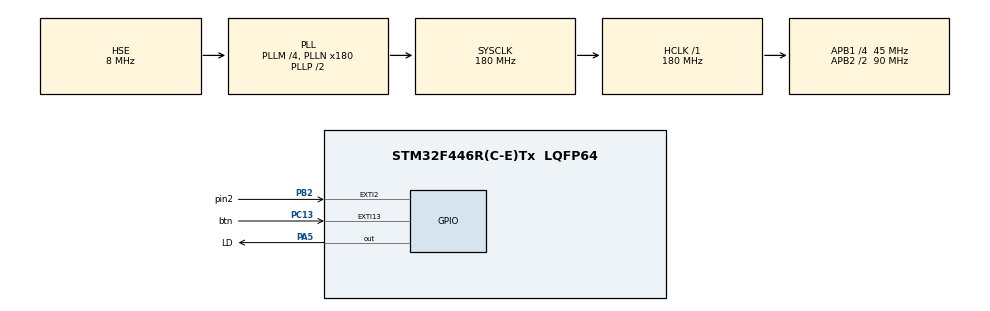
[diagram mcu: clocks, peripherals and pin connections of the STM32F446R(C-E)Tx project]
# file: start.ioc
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FREERTOS.Tasks01=defaultTask,0,128,StartDefaultTask,Default,NULL,Dynamic,NULL,NULL;led_task,0,128,start_led_task,Default,NULL,Dynamic,NULL,NULL;button_task,0,128,start_button_task,Default,NULL,Dynamic,NULL,NULL
FREERTOS.configENABLE_FPU=1
FREERTOS.configUSE_NEWLIB_REENTRANT=1
Mcu.Family=STM32F4
Mcu.Name=STM32F446R(C-E)Tx
Mcu.Package=LQFP64
NVIC.EXTI15_10_IRQn=true\:5\:0\:false\:false\:true\:true\:true\:true\:true
NVIC.EXTI2_IRQn=true\:5\:0\:false\:false\:true\:true\:true\:true\:true
NVIC.PriorityGroup=NVIC_PRIORITYGROUP_4
NVIC.TIM1_UP_TIM10_IRQn=true\:15\:0\:false\:false\:true\:false\:false\:true\:true
NVIC.TimeBase=TIM1_UP_TIM10_IRQn
NVIC.TimeBaseIP=TIM10
PA13.Mode=Serial_Wire
PA13.Signal=SYS_JTMS-SWDIO
PA14.Mode=Serial_Wire
PA14.Signal=SYS_JTCK-SWCLK
PA5.GPIO_Label=LD
PA5.Signal=GPIO_Output
PB2.GPIO_Label=pin2
PB2.GPIO_PuPd=GPIO_PULLUP
PB2.Signal=GPXTI2
PC13.GPIO_Label=btn
PC13.Signal=GPXTI13
PH0-OSC_IN.Mode=HSE-External-Oscillator
PH0-OSC_IN.Signal=RCC_OSC_IN
PH1-OSC_OUT.Mode=HSE-External-Oscillator
PH1-OSC_OUT.Signal=RCC_OSC_OUT
ProjectManager.HeapSize=0x200
ProjectManager.StackSize=0x400
ProjectManager.TargetToolchain=STM32CubeIDE
RCC.AHBFreq_Value=180000000
RCC.APB1CLKDivider=RCC_HCLK_DIV4
RCC.APB1Freq_Value=45000000
RCC.APB1TimFreq_Value=90000000
RCC.APB2CLKDivider=RCC_HCLK_DIV2
RCC.APB2Freq_Value=90000000
RCC.APB2TimFreq_Value=180000000
RCC.CortexFreq_Value=180000000
RCC.FLatency-AdvancedSettings=FLASH_LATENCY_5
RCC.HCLKFreq_Value=180000000
RCC.HSE_VALUE=8000000
RCC.HSI_VALUE=16000000
RCC.PLLM=4
RCC.PLLN=180
RCC.PLLSourceVirtual=RCC_PLLSOURCE_HSE
RCC.SYSCLKFreq_VALUE=180000000
RCC.SYSCLKSource=RCC_SYSCLKSOURCE_PLLCLK
RCC.USBFreq_Value=180000000
RCC.VCOOutputFreq_Value=360000000
VP_FREERTOS_VS_CMSIS_V1.Mode=CMSIS_V1
VP_SYS_VS_tim10.Mode=TIM10
board=NUCLEO-F446RE

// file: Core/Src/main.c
/* USER CODE BEGIN Header */
/**
  ******************************************************************************
  * @file           : main.c
  * @brief          : Main program body
  ******************************************************************************
  * @attention
  *
  * Copyright (c) 2023 STMicroelectronics.
  * All rights reserved.
  *
  * This software is licensed under terms that can be found in the LICENSE file
  * in the root directory of this software component.
  * If no LICENSE file comes with this software, it is provided AS-IS.
  *
  ******************************************************************************
  */
/* USER CODE END Header */
#include "main.h"
#include "cmsis_os.h"
#include "gpio.h"

void SystemClock_Config(void);
void MX_FREERTOS_Init(void);

int main(void)
{

  /* MCU Configuration--------------------------------------------------------*/

  /* Reset of all peripherals, Initializes the Flash interface and the Systick. */
  HAL_Init();

  /* Configure the system clock */
  SystemClock_Config();

  /* Initialize all configured peripherals */
  MX_GPIO_Init();

  /* Call init function for freertos objects (in freertos.c) */
  MX_FREERTOS_Init();

  /* Start scheduler */
  osKernelStart();

  /* We should never get here as control is now taken by the scheduler */
  /* Infinite loop */
  while (1)
  {

  }
}

void SystemClock_Config(void)
{
  RCC_OscInitTypeDef RCC_OscInitStruct = {0};
  RCC_ClkInitTypeDef RCC_ClkInitStruct = {0};

  /** Configure the main internal regulator output voltage
  */
  __HAL_RCC_PWR_CLK_ENABLE();
  __HAL_PWR_VOLTAGESCALING_CONFIG(PWR_REGULATOR_VOLTAGE_SCALE1);

  /** Initializes the RCC Oscillators according to the specified parameters
  * in the RCC_OscInitTypeDef structure.
  */
  RCC_OscInitStruct.OscillatorType = RCC_OSCILLATORTYPE_HSE;
  RCC_OscInitStruct.HSEState = RCC_HSE_ON;
  RCC_OscInitStruct.PLL.PLLState = RCC_PLL_ON;
  RCC_OscInitStruct.PLL.PLLSource = RCC_PLLSOURCE_HSE;
  RCC_OscInitStruct.PLL.PLLM = 4;
  RCC_OscInitStruct.PLL.PLLN = 180;
  RCC_OscInitStruct.PLL.PLLP = RCC_PLLP_DIV2;
  RCC_OscInitStruct.PLL.PLLQ = 2;
  RCC_OscInitStruct.PLL.PLLR = 2;
  if (HAL_RCC_OscConfig(&RCC_OscInitStruct) != HAL_OK)
  {
    Error_Handler();
  }

  /** Activate the Over-Drive mode
  */
  if (HAL_PWREx_EnableOverDrive() != HAL_OK)
  {
    Error_Handler();
  }

  /** Initializes the CPU, AHB and APB buses clocks
  */
  RCC_ClkInitStruct.ClockType = RCC_CLOCKTYPE_HCLK|RCC_CLOCKTYPE_SYSCLK
                              |RCC_CLOCKTYPE_PCLK1|RCC_CLOCKTYPE_PCLK2;
  RCC_ClkInitStruct.SYSCLKSource = RCC_SYSCLKSOURCE_PLLCLK;
  RCC_ClkInitStruct.AHBCLKDivider = RCC_SYSCLK_DIV1;
  RCC_ClkInitStruct.APB1CLKDivider = RCC_HCLK_DIV4;
  RCC_ClkInitStruct.APB2CLKDivider = RCC_HCLK_DIV2;

  if (HAL_RCC_ClockConfig(&RCC_ClkInitStruct, FLASH_LATENCY_5) != HAL_OK)
  {
    Error_Handler();
  }
}

void HAL_TIM_PeriodElapsedCallback(TIM_HandleTypeDef *htim)
{
  if (htim->Instance == TIM10) {
    HAL_IncTick();
  }
}

void Error_Handler(void)
{
  __disable_irq();
  while (1)
  {
  }
}

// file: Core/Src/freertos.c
/* USER CODE BEGIN Header */
/**
  ******************************************************************************
  * File Name          : freertos.c
  * Description        : Code for freertos applications
  ******************************************************************************
  * @attention
  *
  * Copyright (c) 2023 STMicroelectronics.
  * All rights reserved.
  *
  * This software is licensed under terms that can be found in the LICENSE file
  * in the root directory of this software component.
  * If no LICENSE file comes with this software, it is provided AS-IS.
  *
  ******************************************************************************
  */
/* USER CODE END Header */

#include "FreeRTOS.h"
#include "task.h"
#include "main.h"
#include "cmsis_os.h"

/* USER CODE BEGIN Variables */
uint16_t period = 100;
GPIO_PinState pin_state;

/* USER CODE END Variables */
osThreadId defaultTaskHandle;
osThreadId led_taskHandle;
osThreadId button_taskHandle;

void StartDefaultTask(void const * argument);
void start_led_task(void const * argument);
void start_button_task(void const * argument);

void MX_FREERTOS_Init(void); /* (MISRA C 2004 rule 8.1) */

/* GetIdleTaskMemory prototype (linked to static allocation support) */
void vApplicationGetIdleTaskMemory( StaticTask_t **ppxIdleTaskTCBBuffer, StackType_t **ppxIdleTaskStackBuffer, uint32_t *pulIdleTaskStackSize );

/* USER CODE BEGIN GET_IDLE_TASK_MEMORY */
static StaticTask_t xIdleTaskTCBBuffer;
static StackType_t xIdleStack[configMINIMAL_STACK_SIZE];

void vApplicationGetIdleTaskMemory( StaticTask_t **ppxIdleTaskTCBBuffer, StackType_t **ppxIdleTaskStackBuffer, uint32_t *pulIdleTaskStackSize )
{
  *ppxIdleTaskTCBBuffer = &xIdleTaskTCBBuffer;
  *ppxIdleTaskStackBuffer = &xIdleStack[0];
  *pulIdleTaskStackSize = configMINIMAL_STACK_SIZE;
  /* place for user code */
}
/* USER CODE END GET_IDLE_TASK_MEMORY */

void MX_FREERTOS_Init(void) {

  /* Create the thread(s) */
  /* definition and creation of defaultTask */
  osThreadDef(defaultTask, StartDefaultTask, osPriorityNormal, 0, 128);
  defaultTaskHandle = osThreadCreate(osThread(defaultTask), NULL);

  /* definition and creation of led_task */
  osThreadDef(led_task, start_led_task, osPriorityNormal, 0, 128);
  led_taskHandle = osThreadCreate(osThread(led_task), NULL);

  /* definition and creation of button_task */
  osThreadDef(button_task, start_button_task, osPriorityNormal, 0, 128);
  button_taskHandle = osThreadCreate(osThread(button_task), NULL);

}

void StartDefaultTask(void const * argument)
{
  for(;;)
  {
	  osDelay(1);
  }
}

void start_led_task(void const * argument)
{
  /* USER CODE BEGIN start_led_task */
  /* Infinite loop */
  for(;;)
  {
	  HAL_GPIO_TogglePin(LD_GPIO_Port, LD_Pin);
	  osDelay(period);
  }
  /* USER CODE END start_led_task */
}

void start_button_task(void const * argument)
{
  /* USER CODE BEGIN start_button_task */
  /* Infinite loop */
  for(;;)
  {
    if (pin_state==GPIO_PIN_SET) {
      period += 100;
      pin_state = GPIO_PIN_RESET;
    }
    if (period > 1000) {
      period = 100;
    }
	  osDelay(1000);
  }
  /* USER CODE END start_button_task */
}

/* USER CODE BEGIN Application */

void HAL_GPIO_EXTI_Callback(uint16_t GPIO_Pin) {
	if(GPIO_Pin == btn_Pin) {
		pin_state = HAL_GPIO_ReadPin(btn_GPIO_Port, btn_Pin);
	}
	if(GPIO_Pin == pin2_Pin) {
		if(HAL_GPIO_ReadPin(pin2_GPIO_Port, pin2_Pin) == GPIO_PIN_RESET)
			period = 100;
	}
}
/* USER CODE END Application */
